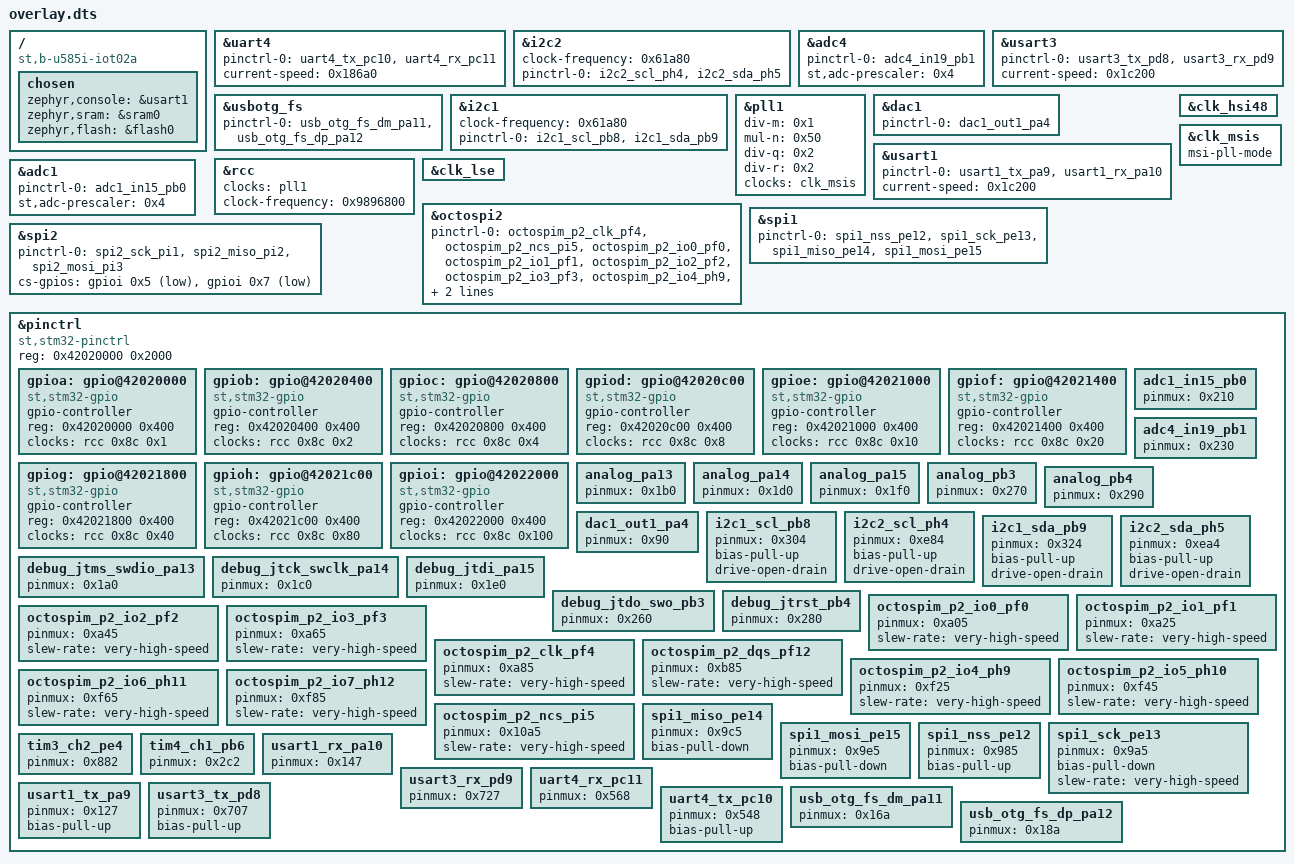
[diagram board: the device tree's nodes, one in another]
/ {
	compatible = "st,b-u585i-iot02a";
	chosen {
		zephyr,console = &usart1;
		zephyr,sram = &sram0;
		zephyr,flash = &flash0;
	};
};
&uart4{
	status = "okay";
	pinctrl-0 = < &uart4_tx_pc10 &uart4_rx_pc11 >;
	pinctrl-names = "default";
	current-speed = < 0x186a0 >;
};
&i2c2{
	clock-frequency = < 0x61a80 >;
	status = "okay";
	pinctrl-0 = < &i2c2_scl_ph4 &i2c2_sda_ph5 >;
	pinctrl-names = "default";
};
&adc4{
	status = "okay";
	pinctrl-0 = < &adc4_in19_pb1 >;
	pinctrl-names = "default";
	st,adc-prescaler = < 0x4 >;
};
&usart3{
	status = "okay";
	pinctrl-0 = < &usart3_tx_pd8 &usart3_rx_pd9 >;
	pinctrl-names = "default";
	current-speed = < 0x1c200 >;
};
&usbotg_fs{
	status = "okay";
	pinctrl-0 = < &usb_otg_fs_dm_pa11 &usb_otg_fs_dp_pa12 >;
	pinctrl-names = "default";
};
&i2c1{
	clock-frequency = < 0x61a80 >;
	status = "okay";
	pinctrl-0 = < &i2c1_scl_pb8 &i2c1_sda_pb9 >;
	pinctrl-names = "default";
};
&pll1{
	status = "okay";
	div-m = < 0x1 >;
	mul-n = < 0x50 >;
	div-q = < 0x2 >;
	div-r = < 0x2 >;
	clocks = < &clk_msis >;
};
&dac1{
	status = "okay";
	pinctrl-0 = < &dac1_out1_pa4 >;
	pinctrl-names = "default";
};
&usart1{
	status = "okay";
	pinctrl-0 = < &usart1_tx_pa9 &usart1_rx_pa10 >;
	pinctrl-names = "default";
	current-speed = < 0x1c200 >;
};
&rcc{
	clocks = < &pll1 >;
	clock-frequency = < 0x9896800 >;
};
&clk_hsi48{
	status = "okay";
};
&clk_msis{
	status = "okay";
	msi-pll-mode;
};
&clk_lse{
	status = "okay";
};
&octospi2{
	status = "okay";
	pinctrl-0 = < &octospim_p2_clk_pf4 &octospim_p2_ncs_pi5 &octospim_p2_io0_pf0 &octospim_p2_io1_pf1 &octospim_p2_io2_pf2 &octospim_p2_io3_pf3 &octospim_p2_io4_ph9 &octospim_p2_io5_ph10 &octospim_p2_io6_ph11 &octospim_p2_io7_ph12 &octospim_p2_dqs_pf12 >;
	pinctrl-names = "default";
};
&adc1{
	status = "okay";
	pinctrl-0 = < &adc1_in15_pb0 >;
	pinctrl-names = "default";
	st,adc-prescaler = < 0x4 >;
};
&spi1{
	status = "okay";
	pinctrl-0 = < &spi1_nss_pe12 &spi1_sck_pe13 &spi1_miso_pe14 &spi1_mosi_pe15 >;
	pinctrl-names = "default";
};
&gpioi{
	status = "okay";
};
&spi2{
	status = "okay";
	pinctrl-0 = < &spi2_sck_pi1 &spi2_miso_pi2 &spi2_mosi_pi3 >;
	pinctrl-names = "default";
	cs-gpios = < &gpioi 0x5 0x1 >, < &gpioi 0x7 0x1 >;
};
&pinctrl{
	compatible = "st,stm32-pinctrl";
	#address-cells = < 0x1 >;
	#size-cells = < 0x1 >;
	reg = < 0x42020000 0x2000 >;
	gpioa: gpio@42020000 {
		compatible = "st,stm32-gpio";
		gpio-controller;
		#gpio-cells = < 0x2 >;
		reg = < 0x42020000 0x400 >;
		clocks = < &rcc 0x8c 0x1 >;
	};
	gpiob: gpio@42020400 {
		compatible = "st,stm32-gpio";
		gpio-controller;
		#gpio-cells = < 0x2 >;
		reg = < 0x42020400 0x400 >;
		clocks = < &rcc 0x8c 0x2 >;
	};
	gpioc: gpio@42020800 {
		compatible = "st,stm32-gpio";
		gpio-controller;
		#gpio-cells = < 0x2 >;
		reg = < 0x42020800 0x400 >;
		clocks = < &rcc 0x8c 0x4 >;
	};
	gpiod: gpio@42020c00 {
		compatible = "st,stm32-gpio";
		gpio-controller;
		#gpio-cells = < 0x2 >;
		reg = < 0x42020c00 0x400 >;
		clocks = < &rcc 0x8c 0x8 >;
	};
	gpioe: gpio@42021000 {
		compatible = "st,stm32-gpio";
		gpio-controller;
		#gpio-cells = < 0x2 >;
		reg = < 0x42021000 0x400 >;
		clocks = < &rcc 0x8c 0x10 >;
	};
	gpiof: gpio@42021400 {
		compatible = "st,stm32-gpio";
		gpio-controller;
		#gpio-cells = < 0x2 >;
		reg = < 0x42021400 0x400 >;
		clocks = < &rcc 0x8c 0x20 >;
	};
	gpiog: gpio@42021800 {
		compatible = "st,stm32-gpio";
		gpio-controller;
		#gpio-cells = < 0x2 >;
		reg = < 0x42021800 0x400 >;
		clocks = < &rcc 0x8c 0x40 >;
	};
	gpioh: gpio@42021c00 {
		compatible = "st,stm32-gpio";
		gpio-controller;
		#gpio-cells = < 0x2 >;
		reg = < 0x42021c00 0x400 >;
		clocks = < &rcc 0x8c 0x80 >;
	};
	gpioi: gpio@42022000 {
		compatible = "st,stm32-gpio";
		gpio-controller;
		#gpio-cells = < 0x2 >;
		reg = < 0x42022000 0x400 >;
		clocks = < &rcc 0x8c 0x100 >;
	};
	adc1_in15_pb0: adc1_in15_pb0 {
		pinmux = < 0x210 >;
	};
	adc4_in19_pb1: adc4_in19_pb1 {
		pinmux = < 0x230 >;
	};
	analog_pa13: analog_pa13 {
		pinmux = < 0x1b0 >;
	};
	analog_pa14: analog_pa14 {
		pinmux = < 0x1d0 >;
	};
	analog_pa15: analog_pa15 {
		pinmux = < 0x1f0 >;
	};
	analog_pb3: analog_pb3 {
		pinmux = < 0x270 >;
	};
	analog_pb4: analog_pb4 {
		pinmux = < 0x290 >;
	};
	dac1_out1_pa4: dac1_out1_pa4 {
		pinmux = < 0x90 >;
	};
	i2c1_scl_pb8: i2c1_scl_pb8 {
		pinmux = < 0x304 >;
		bias-pull-up;
		drive-open-drain;
	};
	i2c2_scl_ph4: i2c2_scl_ph4 {
		pinmux = < 0xe84 >;
		bias-pull-up;
		drive-open-drain;
	};
	i2c1_sda_pb9: i2c1_sda_pb9 {
		pinmux = < 0x324 >;
		bias-pull-up;
		drive-open-drain;
	};
	i2c2_sda_ph5: i2c2_sda_ph5 {
		pinmux = < 0xea4 >;
		bias-pull-up;
		drive-open-drain;
	};
	debug_jtms_swdio_pa13: debug_jtms_swdio_pa13 {
		pinmux = < 0x1a0 >;
	};
	debug_jtck_swclk_pa14: debug_jtck_swclk_pa14 {
		pinmux = < 0x1c0 >;
	};
	debug_jtdi_pa15: debug_jtdi_pa15 {
		pinmux = < 0x1e0 >;
	};
	debug_jtdo_swo_pb3: debug_jtdo_swo_pb3 {
		pinmux = < 0x260 >;
	};
	debug_jtrst_pb4: debug_jtrst_pb4 {
		pinmux = < 0x280 >;
	};
	octospim_p2_io0_pf0: octospim_p2_io0_pf0 {
		pinmux = < 0xa05 >;
		slew-rate = "very-high-speed";
	};
	octospim_p2_io1_pf1: octospim_p2_io1_pf1 {
		pinmux = < 0xa25 >;
		slew-rate = "very-high-speed";
	};
	octospim_p2_io2_pf2: octospim_p2_io2_pf2 {
		pinmux = < 0xa45 >;
		slew-rate = "very-high-speed";
	};
	octospim_p2_io3_pf3: octospim_p2_io3_pf3 {
		pinmux = < 0xa65 >;
		slew-rate = "very-high-speed";
	};
	octospim_p2_clk_pf4: octospim_p2_clk_pf4 {
		pinmux = < 0xa85 >;
		slew-rate = "very-high-speed";
	};
	octospim_p2_dqs_pf12: octospim_p2_dqs_pf12 {
		pinmux = < 0xb85 >;
		slew-rate = "very-high-speed";
	};
	octospim_p2_io4_ph9: octospim_p2_io4_ph9 {
		pinmux = < 0xf25 >;
		slew-rate = "very-high-speed";
	};
	octospim_p2_io5_ph10: octospim_p2_io5_ph10 {
		pinmux = < 0xf45 >;
		slew-rate = "very-high-speed";
	};
	octospim_p2_io6_ph11: octospim_p2_io6_ph11 {
		pinmux = < 0xf65 >;
		slew-rate = "very-high-speed";
	};
	octospim_p2_io7_ph12: octospim_p2_io7_ph12 {
		pinmux = < 0xf85 >;
		slew-rate = "very-high-speed";
	};
	octospim_p2_ncs_pi5: octospim_p2_ncs_pi5 {
		pinmux = < 0x10a5 >;
		slew-rate = "very-high-speed";
	};
	spi1_miso_pe14: spi1_miso_pe14 {
		pinmux = < 0x9c5 >;
		bias-pull-down;
	};
	spi1_mosi_pe15: spi1_mosi_pe15 {
		pinmux = < 0x9e5 >;
		bias-pull-down;
	};
	spi1_nss_pe12: spi1_nss_pe12 {
		pinmux = < 0x985 >;
		bias-pull-up;
	};
	spi1_sck_pe13: spi1_sck_pe13 {
		pinmux = < 0x9a5 >;
		bias-pull-down;
		slew-rate = "very-high-speed";
	};
	tim3_ch2_pe4: tim3_ch2_pe4 {
		pinmux = < 0x882 >;
	};
	tim4_ch1_pb6: tim4_ch1_pb6 {
		pinmux = < 0x2c2 >;
	};
	usart1_rx_pa10: usart1_rx_pa10 {
		pinmux = < 0x147 >;
	};
	usart3_rx_pd9: usart3_rx_pd9 {
		pinmux = < 0x727 >;
	};
	uart4_rx_pc11: uart4_rx_pc11 {
		pinmux = < 0x568 >;
	};
	usart1_tx_pa9: usart1_tx_pa9 {
		pinmux = < 0x127 >;
		bias-pull-up;
	};
	usart3_tx_pd8: usart3_tx_pd8 {
		pinmux = < 0x707 >;
		bias-pull-up;
	};
	uart4_tx_pc10: uart4_tx_pc10 {
		pinmux = < 0x548 >;
		bias-pull-up;
	};
	usb_otg_fs_dm_pa11: usb_otg_fs_dm_pa11 {
		pinmux = < 0x16a >;
	};
	usb_otg_fs_dp_pa12: usb_otg_fs_dp_pa12 {
		pinmux = < 0x18a >;
	};
};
